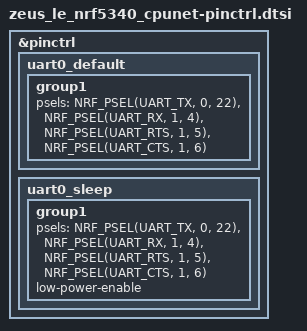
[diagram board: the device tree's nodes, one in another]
/*
 * Copyright (c) 2024 Ben Wolsieffer
 *
 * SPDX-License-Identifier: Apache-2.0
 */

&pinctrl {
	uart0_default: uart0_default {
		group1 {
			psels = <NRF_PSEL(UART_TX, 0, 22)>,
				<NRF_PSEL(UART_RX, 1, 4)>,
				<NRF_PSEL(UART_RTS, 1, 5)>,
				<NRF_PSEL(UART_CTS, 1, 6)>;
		};
	};

	uart0_sleep: uart0_sleep {
		group1 {
			psels = <NRF_PSEL(UART_TX, 0, 22)>,
				<NRF_PSEL(UART_RX, 1, 4)>,
				<NRF_PSEL(UART_RTS, 1, 5)>,
				<NRF_PSEL(UART_CTS, 1, 6)>;
			low-power-enable;
		};
	};

};
